# Port_F_2 register map
Vendor: Texas Instruments
Peripheral module from a debugger description file (folder msp430).
Registers are 16-bit, read-write, reset 0x0 unless marked. A register's access mark holds for its fields unless they carry their own. Offsets are as the file gives them; lines under a group give offsets from that group; [hi:lo] are bit positions; {n}, {i} and the like mark numbered series; 'fields as' and 'values as' point back to an identical list; <NAME> marks a mode.

## Port_F
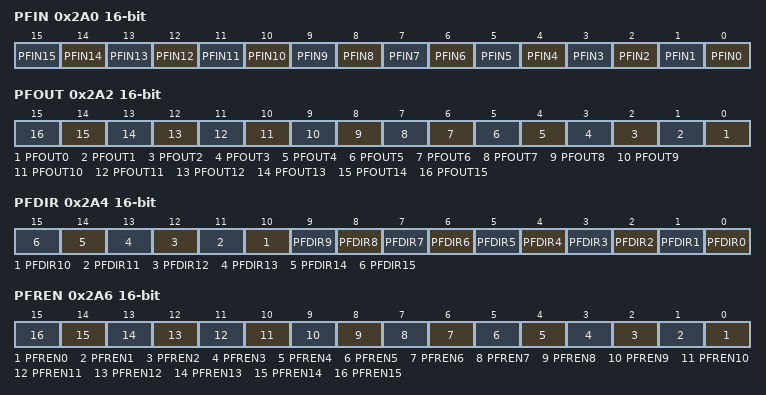
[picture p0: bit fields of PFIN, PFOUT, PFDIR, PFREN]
0x2A0 PFIN — Port F Input
  [n] PFIN{n} (n=0..15)
0x2A2 PFOUT — Port F Output
  [n] PFOUT{n} (n=0..15)
0x2A4 PFDIR — Port F Direction
  [n] PFDIR{n} (n=0..15)
0x2A6 PFREN — Port F Resistor Enable
  [n] PFREN{n} (n=0..15)
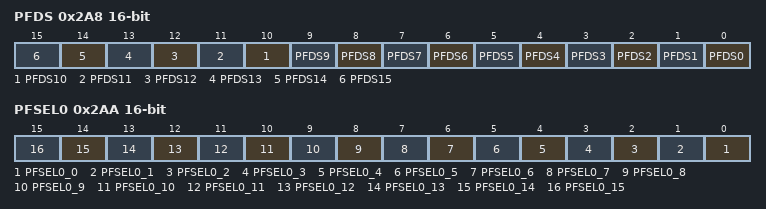
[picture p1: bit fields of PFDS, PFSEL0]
0x2A8 PFDS — Port F Drive Strenght
  [n] PFDS{n} (n=0..15)
0x2AA PFSEL0 — Port F Selection 0
  [n] PFSEL0_{n} (n=0..15)
